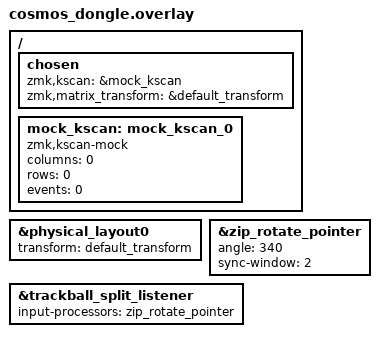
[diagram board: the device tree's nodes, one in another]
// Can't have the kscan0 here, that one's physical
/* 
    Central side is the only one that is aware of .keymap,
    so put all input processors you want to take effect in input listener here.
*/

#include "cosmos.dtsi"
#include "split_input.dtsi"
#include "cosmos-layouts.dtsi"
#include <input/processors.dtsi>
#include <dt-bindings/zmk/input_transform.h>
#include <dt-bindings/zmk/matrix_transform.h>

&physical_layout0 {
    transform = <&default_transform>;
};

#include <input/processors/rotate_plane.dtsi>
&zip_rotate_pointer {
	angle = <340>;
	sync-window = <2>; // msec
};
#include <input/processors/rotate_plane.dtsi>
&zip_rotate_pointer {
	angle = <340>;
	sync-window = <2>; // msec
};
&trackball_split_listener { // local trackball input split device child node, receiving events from the peripheral and raising them locally
	status = "okay";
    input-processors = <&zip_rotate_pointer>;

//    	input-processors = 
//		    <&pointer_accel>;
//	scroll {
//		layers = <5>; // SCROLL
//		input-processors =
//            <&zip_xy_transform (INPUT_TRANSFORM_Y_INVERT)>,
//            <&zip_xy_scaler 1 16>,
//            <&zip_xy_to_scroll_mapper>;
//	};
};

/ {
    chosen {
        zmk,kscan = &mock_kscan;
        zmk,matrix_transform = &default_transform;
    };

    mock_kscan: mock_kscan_0 {
        compatible = "zmk,kscan-mock";
        columns = <0>;
        rows = <0>;
        events = <0>;
    };
};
